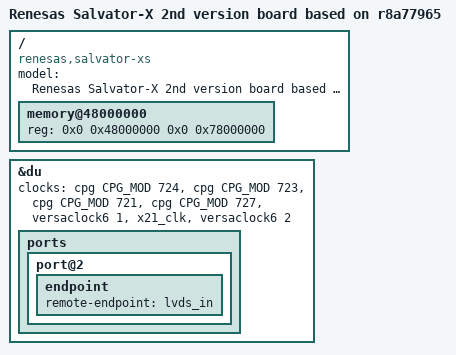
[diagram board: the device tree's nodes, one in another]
/*
 * Device Tree Source for the Salvator-X 2nd version board
 *
 * Copyright (C) 2017 Renesas Electronics Corp.
 *
 * This file is licensed under the terms of the GNU General Public License
 * version 2.  This program is licensed "as is" without any warranty of any
 * kind, whether express or implied.
 */

/dts-v1/;
#include "r8a77965.dtsi"
#include "salvator-xs.dtsi"

/ {
	model = "Renesas Salvator-X 2nd version board based on r8a77965";
	compatible = "renesas,salvator-xs", "renesas,r8a77965";

	memory@48000000 {
		device_type = "memory";
		/* first 128MB is reserved for secure area. */
		reg = <0x0 0x48000000 0x0 0x78000000>;
	};
};

&du {
	clocks = <&cpg CPG_MOD 724>,
		 <&cpg CPG_MOD 723>,
		 <&cpg CPG_MOD 721>,
		 <&cpg CPG_MOD 727>,
		 <&versaclock6 1>,
		 <&x21_clk>,
		 <&versaclock6 2>;
	clock-names = "du.0", "du.1", "du.3", "lvds.0",
		      "dclkin.0", "dclkin.1", "dclkin.3";

	ports {
		port@2 {
			endpoint {
				remote-endpoint = <&lvds_in>;
			};
		};
	};
};
